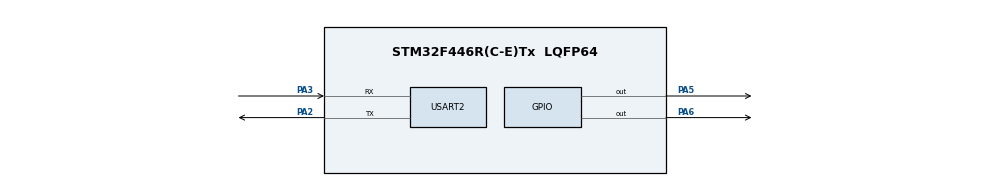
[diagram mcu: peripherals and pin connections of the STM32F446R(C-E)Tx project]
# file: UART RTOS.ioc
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FREERTOS.Tasks01=Task1,24,128,StartTask1,Default,NULL,Dynamic,NULL,NULL;Task02,24,128,StartTask02,Default,NULL,Dynamic,NULL,NULL;Task03,32,128,StartTask03,Default,NULL,Dynamic,NULL,NULL
Mcu.Family=STM32F4
Mcu.Name=STM32F446R(C-E)Tx
Mcu.Package=LQFP64
NVIC.PriorityGroup=NVIC_PRIORITYGROUP_4
PA2.Mode=Asynchronous
PA2.Signal=USART2_TX
PA3.Mode=Asynchronous
PA3.Signal=USART2_RX
PA5.Signal=GPIO_Output
PA6.Signal=GPIO_Output
ProjectManager.HeapSize=0x200
ProjectManager.StackSize=0x400
ProjectManager.TargetToolchain=STM32CubeIDE
RCC.CortexFreq_Value=16000000
RCC.USBFreq_Value=96000000
RCC.VCOOutputFreq_Value=192000000
USART2.VirtualMode=VM_ASYNC
VP_FREERTOS_VS_CMSIS_V2.Mode=CMSIS_V2
board=custom

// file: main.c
/* USER CODE BEGIN Header */
/**
  ******************************************************************************
  * @file           : main.c
  * @brief          : Main program body
  ******************************************************************************
  * @attention
  *
  * Copyright (c) 2026 STMicroelectronics.
  * All rights reserved.
  *
  * This software is licensed under terms that can be found in the LICENSE file
  * in the root directory of this software component.
  * If no LICENSE file comes with this software, it is provided AS-IS.
  *
  ******************************************************************************
  */
/* USER CODE END Header */
#include "main.h"
#include "cmsis_os.h"

/* USER CODE BEGIN Includes */
#include <string.h>
#include <stdio.h>
/* USER CODE END Includes */

/* USER CODE BEGIN PD */
#define LED1_SELECTED    1
#define LED2_SELECTED    2
/* USER CODE END PD */

UART_HandleTypeDef huart2;

/* Definitions for Task1 */
osThreadId_t Task1Handle;
const osThreadAttr_t Task1_attributes = {
  .name = "Task1",
  .stack_size = 128 * 4,
  .priority = (osPriority_t) osPriorityNormal,
};

/* Definitions for Task02 */
osThreadId_t Task02Handle;
const osThreadAttr_t Task02_attributes = {
  .name = "Task02",
  .stack_size = 128 * 4,
  .priority = (osPriority_t) osPriorityNormal,
};

/* Definitions for Task03 */
osThreadId_t Task03Handle;
const osThreadAttr_t Task03_attributes = {
  .name = "Task03",
  .stack_size = 128 * 4,
  .priority = (osPriority_t) osPriorityAboveNormal,
};

/* USER CODE BEGIN PV */
uint8_t rxData;
volatile uint8_t activeLed = LED1_SELECTED;
/* USER CODE END PV */

void SystemClock_Config(void);
static void MX_GPIO_Init(void);
static void MX_USART2_UART_Init(void);
void StartTask1(void *argument);
void StartTask02(void *argument);
void StartTask03(void *argument);

/* USER CODE BEGIN PFP */
void UART_SendString(char *str);
/* USER CODE END PFP */

/* USER CODE BEGIN 0 */
void UART_SendString(char *str)
{
  HAL_UART_Transmit(&huart2, (uint8_t *)str, strlen(str), HAL_MAX_DELAY);
}
/* USER CODE END 0 */

int main(void)
{

  /* MCU Configuration--------------------------------------------------------*/
  HAL_Init();

  SystemClock_Config();

  MX_GPIO_Init();
  MX_USART2_UART_Init();

  /* USER CODE BEGIN 2 */
  UART_SendString("System Started\r\n");
  UART_SendString("Send '1' for PA5 LED blink\r\n");
  UART_SendString("Send '2' for PA6 LED blink\r\n");
  /* USER CODE END 2 */

  osKernelInitialize();

  /* Create the thread(s) */
  Task1Handle = osThreadNew(StartTask1, NULL, &Task1_attributes);
  Task02Handle = osThreadNew(StartTask02, NULL, &Task02_attributes);
  Task03Handle = osThreadNew(StartTask03, NULL, &Task03_attributes);

  osKernelStart();

  while (1)
  {
  }
}

void SystemClock_Config(void)
{
  RCC_OscInitTypeDef RCC_OscInitStruct = {0};
  RCC_ClkInitTypeDef RCC_ClkInitStruct = {0};

  __HAL_RCC_PWR_CLK_ENABLE();
  __HAL_PWR_VOLTAGESCALING_CONFIG(PWR_REGULATOR_VOLTAGE_SCALE3);

  RCC_OscInitStruct.OscillatorType = RCC_OSCILLATORTYPE_HSI;
  RCC_OscInitStruct.HSIState = RCC_HSI_ON;
  RCC_OscInitStruct.HSICalibrationValue = RCC_HSICALIBRATION_DEFAULT;
  RCC_OscInitStruct.PLL.PLLState = RCC_PLL_NONE;
  if (HAL_RCC_OscConfig(&RCC_OscInitStruct) != HAL_OK)
  {
    Error_Handler();
  }

  RCC_ClkInitStruct.ClockType = RCC_CLOCKTYPE_HCLK | RCC_CLOCKTYPE_SYSCLK
                              | RCC_CLOCKTYPE_PCLK1 | RCC_CLOCKTYPE_PCLK2;
  RCC_ClkInitStruct.SYSCLKSource = RCC_SYSCLKSOURCE_HSI;
  RCC_ClkInitStruct.AHBCLKDivider = RCC_SYSCLK_DIV1;
  RCC_ClkInitStruct.APB1CLKDivider = RCC_HCLK_DIV1;
  RCC_ClkInitStruct.APB2CLKDivider = RCC_HCLK_DIV1;

  if (HAL_RCC_ClockConfig(&RCC_ClkInitStruct, FLASH_LATENCY_0) != HAL_OK)
  {
    Error_Handler();
  }
}

static void MX_USART2_UART_Init(void)
{
  huart2.Instance = USART2;
  huart2.Init.BaudRate = 115200;
  huart2.Init.WordLength = UART_WORDLENGTH_8B;
  huart2.Init.StopBits = UART_STOPBITS_1;
  huart2.Init.Parity = UART_PARITY_NONE;
  huart2.Init.Mode = UART_MODE_TX_RX;
  huart2.Init.HwFlowCtl = UART_HWCONTROL_NONE;
  huart2.Init.OverSampling = UART_OVERSAMPLING_16;

  if (HAL_UART_Init(&huart2) != HAL_OK)
  {
    Error_Handler();
  }
}

static void MX_GPIO_Init(void)
{
  GPIO_InitTypeDef GPIO_InitStruct = {0};

  __HAL_RCC_GPIOA_CLK_ENABLE();

  HAL_GPIO_WritePin(GPIOA, GPIO_PIN_5 | GPIO_PIN_6, GPIO_PIN_RESET);

  GPIO_InitStruct.Pin = GPIO_PIN_5 | GPIO_PIN_6;
  GPIO_InitStruct.Mode = GPIO_MODE_OUTPUT_PP;
  GPIO_InitStruct.Pull = GPIO_NOPULL;
  GPIO_InitStruct.Speed = GPIO_SPEED_FREQ_LOW;
  HAL_GPIO_Init(GPIOA, &GPIO_InitStruct);
}

void StartTask1(void *argument)
{
  for (;;)
  {
    if (activeLed == LED1_SELECTED)
    {
      HAL_GPIO_TogglePin(GPIOA, GPIO_PIN_5);
      osDelay(500);
    }
    else
    {
      HAL_GPIO_WritePin(GPIOA, GPIO_PIN_5, GPIO_PIN_RESET);
      osDelay(20);
    }
  }
}

void StartTask02(void *argument)
{
  for (;;)
  {
    if (activeLed == LED2_SELECTED)
    {
      HAL_GPIO_TogglePin(GPIOA, GPIO_PIN_6);
      osDelay(200);
    }
    else
    {
      HAL_GPIO_WritePin(GPIOA, GPIO_PIN_6, GPIO_PIN_RESET);
      osDelay(20);
    }
  }
}

void StartTask03(void *argument)
{
  char msg[50];

  for (;;)
  {
    if (HAL_UART_Receive(&huart2, &rxData, 1, 100) == HAL_OK)
    {
      if (rxData == '1')
      {
        activeLed = LED1_SELECTED;
        HAL_GPIO_WritePin(GPIOA, GPIO_PIN_6, GPIO_PIN_RESET);

        sprintf(msg, "LED on PA5 selected\r\n");
        UART_SendString(msg);
      }
      else if (rxData == '2')
      {
        activeLed = LED2_SELECTED;
        HAL_GPIO_WritePin(GPIOA, GPIO_PIN_5, GPIO_PIN_RESET);

        sprintf(msg, "LED on PA6 selected\r\n");
        UART_SendString(msg);
      }
      else
      {
        sprintf(msg, "Invalid input: %c\r\n", rxData);
        UART_SendString(msg);
      }
    }

    osDelay(10);
  }
}

void Error_Handler(void)
{
  __disable_irq();
  while (1)
  {
  }
}
